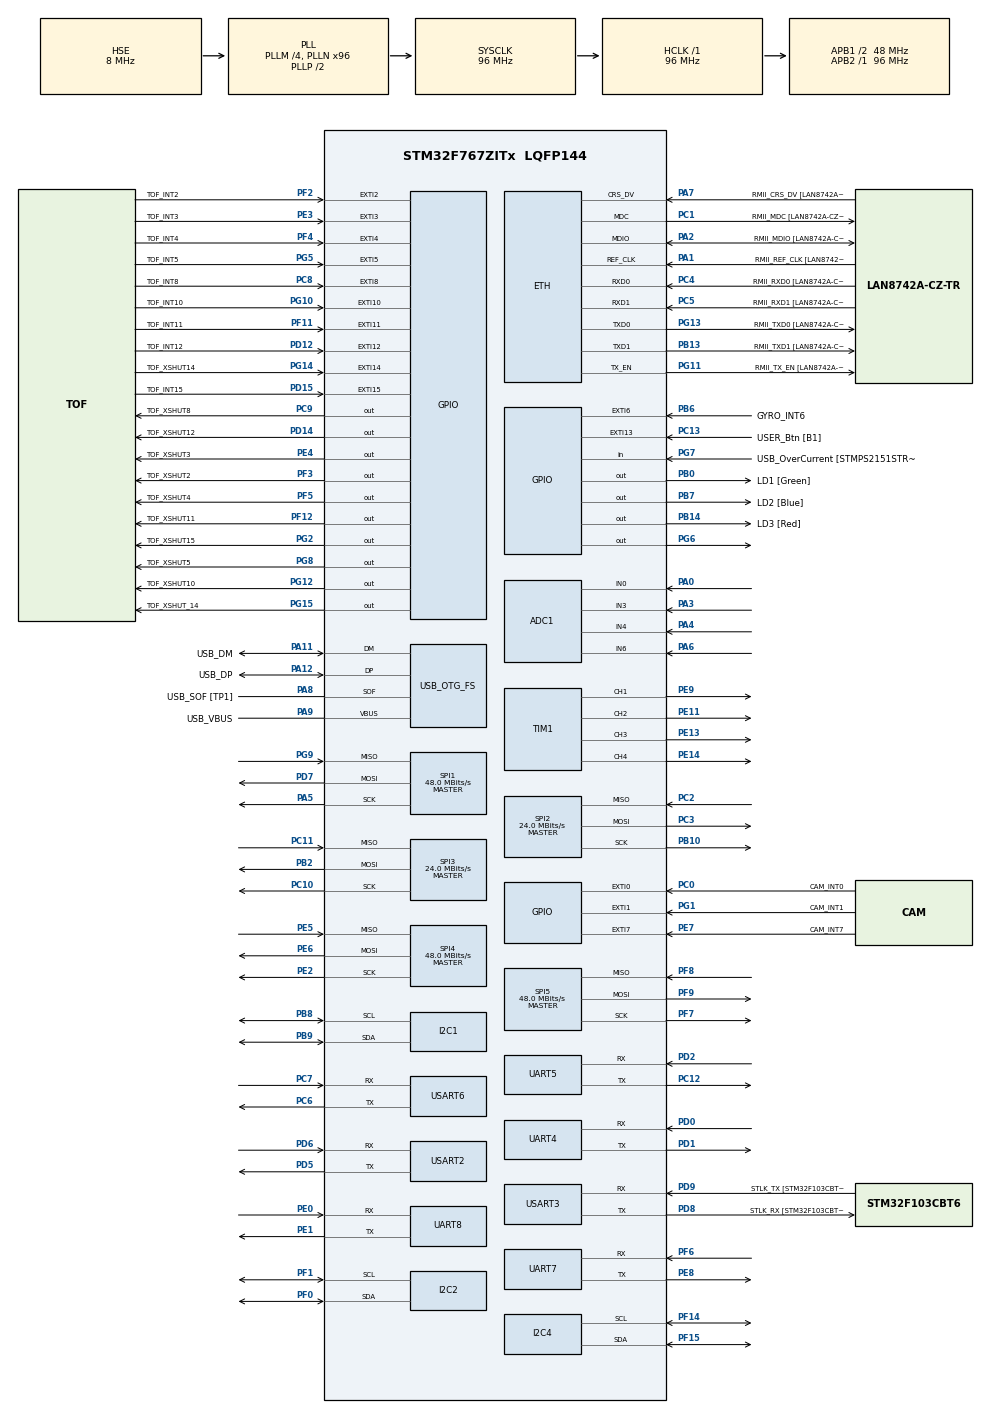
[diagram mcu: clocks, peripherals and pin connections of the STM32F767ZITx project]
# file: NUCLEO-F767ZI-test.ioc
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ADC1.Channel-0\#ChannelRegularConversion=ADC_CHANNEL_0
ADC1.NbrOfConversionFlag=1
ADC1.Rank-0\#ChannelRegularConversion=1
ADC1.SamplingTime-0\#ChannelRegularConversion=ADC_SAMPLETIME_3CYCLES
ADC1.master=1
ETH.MediaInterface=HAL_ETH_RMII_MODE
ETH.PHY_Name=LAN8742A_PHY_ADDRESS
ETH.PHY_Value=0
ETH.PhyAddress=0
I2C1.Timing=0x20303E5D
I2C2.Timing=0x20303E5D
I2C4.Timing=0x20303E5D
Mcu.Family=STM32F7
Mcu.Name=STM32F767ZITx
Mcu.Package=LQFP144
NVIC.PriorityGroup=NVIC_PRIORITYGROUP_4
PA0/WKUP.Signal=ADCx_IN0
PA1.GPIO_Label=RMII_REF_CLK [LAN8742A-CZ-TR_REFCLK0]
PA1.Mode=RMII
PA1.Signal=ETH_REF_CLK
PA10.GPIO_Label=USB_ID
PA10.Signal=USB_OTG_FS_ID
PA11.GPIO_Label=USB_DM
PA11.Mode=Device_Only
PA11.Signal=USB_OTG_FS_DM
PA12.GPIO_Label=USB_DP
PA12.Mode=Device_Only
PA12.Signal=USB_OTG_FS_DP
PA13.GPIO_Label=TMS
PA13.Mode=JTAG_5_pins
PA13.Signal=SYS_JTMS-SWDIO
PA14.GPIO_Label=TCK
PA14.Mode=JTAG_5_pins
PA14.Signal=SYS_JTCK-SWCLK
PA15.Mode=JTAG_5_pins
PA15.Signal=SYS_JTDI
PA2.GPIO_Label=RMII_MDIO [LAN8742A-CZ-TR_MDIO]
PA2.Mode=RMII
PA2.Signal=ETH_MDIO
PA3.Signal=ADCx_IN3
PA4.Signal=ADCx_IN4
PA5.Mode=Full_Duplex_Master
PA5.Signal=SPI1_SCK
PA6.Signal=ADCx_IN6
PA7.GPIO_Label=RMII_CRS_DV [LAN8742A-CZ-TR_CRS_DV]
PA7.Mode=RMII
PA7.Signal=ETH_CRS_DV
PA8.GPIO_Label=USB_SOF [TP1]
PA8.Mode=Activate_SOF_FS
PA8.Signal=USB_OTG_FS_SOF
PA9.GPIO_Label=USB_VBUS
PA9.Mode=Activate_VBUS
PA9.Signal=USB_OTG_FS_VBUS
PB0.GPIO_Label=LD1 [Green]
PB0.Signal=GPIO_Output
PB10.Mode=Full_Duplex_Master
PB10.Signal=SPI2_SCK
PB13.GPIO_Label=RMII_TXD1 [LAN8742A-CZ-TR_TXD1]
PB13.Mode=RMII
PB13.Signal=ETH_TXD1
PB14.GPIO_Label=LD3 [Red]
PB14.Signal=GPIO_Output
PB2.Mode=Full_Duplex_Master
PB2.Signal=SPI3_MOSI
PB3.GPIO_Label=SWO
PB3.Mode=JTAG_5_pins
PB3.Signal=SYS_JTDO-SWO
PB4.Mode=JTAG_5_pins
PB4.Signal=SYS_JTRST
PB6.GPIO_Label=GYRO_INT6
PB6.Signal=GPXTI6
PB7.GPIO_Label=LD2 [Blue]
PB7.Signal=GPIO_Output
PB8.Mode=I2C
PB8.Signal=I2C1_SCL
PB9.Mode=I2C
PB9.Signal=I2C1_SDA
PC0.GPIO_Label=CAM_INT0
PC0.Signal=GPXTI0
PC1.GPIO_Label=RMII_MDC [LAN8742A-CZ-TR_MDC]
PC1.Mode=RMII
PC1.Signal=ETH_MDC
PC10.Mode=Full_Duplex_Master
PC10.Signal=SPI3_SCK
PC11.Mode=Full_Duplex_Master
PC11.Signal=SPI3_MISO
PC12.Mode=Asynchronous
PC12.Signal=UART5_TX
PC13.GPIO_Label=USER_Btn [B1]
PC13.Signal=GPXTI13
PC14/OSC32_IN.Mode=LSE-External-Oscillator
PC14/OSC32_IN.Signal=RCC_OSC32_IN
PC15/OSC32_OUT.Mode=LSE-External-Oscillator
PC15/OSC32_OUT.Signal=RCC_OSC32_OUT
PC2.Mode=Full_Duplex_Master
PC2.Signal=SPI2_MISO
PC3.Mode=Full_Duplex_Master
PC3.Signal=SPI2_MOSI
PC4.GPIO_Label=RMII_RXD0 [LAN8742A-CZ-TR_RXD0]
PC4.Mode=RMII
PC4.Signal=ETH_RXD0
PC5.GPIO_Label=RMII_RXD1 [LAN8742A-CZ-TR_RXD1]
PC5.Mode=RMII
PC5.Signal=ETH_RXD1
PC6.Mode=Asynchronous
PC6.Signal=USART6_TX
PC7.Mode=Asynchronous
PC7.Signal=USART6_RX
PC8.GPIO_Label=TOF_INT8
PC8.Signal=GPXTI8
PC9.GPIO_Label=TOF_XSHUT8
PC9.Signal=GPIO_Output
PD0.Mode=Asynchronous
PD0.Signal=UART4_RX
PD1.Mode=Asynchronous
PD1.Signal=UART4_TX
PD12.GPIO_Label=TOF_INT12
PD12.Signal=GPXTI12
PD14.GPIO_Label=TOF_XSHUT12
PD14.Signal=GPIO_Output
PD15.GPIO_Label=TOF_INT15
PD15.Signal=GPXTI15
PD2.Mode=Asynchronous
PD2.Signal=UART5_RX
PD5.Mode=Asynchronous
PD5.Signal=USART2_TX
PD6.Mode=Asynchronous
PD6.Signal=USART2_RX
PD7.Mode=Full_Duplex_Master
PD7.Signal=SPI1_MOSI
PD8.GPIO_Label=STLK_RX [STM32F103CBT6_PA3]
PD8.Mode=Asynchronous
PD8.Signal=USART3_TX
PD9.GPIO_Label=STLK_TX [STM32F103CBT6_PA2]
PD9.Mode=Asynchronous
PD9.Signal=USART3_RX
PE0.Mode=Asynchronous
PE0.Signal=UART8_RX
PE1.Mode=Asynchronous
PE1.Signal=UART8_TX
PE11.Signal=S_TIM1_CH2
PE13.Signal=S_TIM1_CH3
PE14.Signal=S_TIM1_CH4
PE2.Mode=Full_Duplex_Master
PE2.Signal=SPI4_SCK
PE3.GPIO_Label=TOF_INT3
PE3.Signal=GPXTI3
PE4.GPIO_Label=TOF_XSHUT3
PE4.Signal=GPIO_Output
PE5.Mode=Full_Duplex_Master
PE5.Signal=SPI4_MISO
PE6.Mode=Full_Duplex_Master
PE6.Signal=SPI4_MOSI
PE7.GPIO_Label=CAM_INT7
PE7.Signal=GPXTI7
PE8.Mode=Asynchronous
PE8.Signal=UART7_TX
PE9.Signal=S_TIM1_CH1
PF0.Mode=I2C
PF0.Signal=I2C2_SDA
PF1.Mode=I2C
PF1.Signal=I2C2_SCL
PF11.GPIO_Label=TOF_INT11
PF11.Signal=GPXTI11
PF12.GPIO_Label=TOF_XSHUT11
PF12.Signal=GPIO_Output
PF14.Mode=I2C
PF14.Signal=I2C4_SCL
PF15.Mode=I2C
PF15.Signal=I2C4_SDA
PF2.GPIO_Label=TOF_INT2
PF2.Signal=GPXTI2
PF3.GPIO_Label=TOF_XSHUT2
PF3.Signal=GPIO_Output
PF4.GPIO_Label=TOF_INT4
PF4.Signal=GPXTI4
PF5.GPIO_Label=TOF_XSHUT4
PF5.Signal=GPIO_Output
PF6.Mode=Asynchronous
PF6.Signal=UART7_RX
PF7.Mode=Full_Duplex_Master
PF7.Signal=SPI5_SCK
PF8.Mode=Full_Duplex_Master
PF8.Signal=SPI5_MISO
PF9.Mode=Full_Duplex_Master
PF9.Signal=SPI5_MOSI
PG1.GPIO_Label=CAM_INT1
PG1.Signal=GPXTI1
PG10.GPIO_Label=TOF_INT10
PG10.Signal=GPXTI10
PG11.GPIO_Label=RMII_TX_EN [LAN8742A-CZ-TR_TXEN]
PG11.Mode=RMII
PG11.Signal=ETH_TX_EN
PG12.GPIO_Label=TOF_XSHUT10
PG12.Signal=GPIO_Output
PG13.GPIO_Label=RMII_TXD0 [LAN8742A-CZ-TR_TXD0]
PG13.Mode=RMII
PG13.Signal=ETH_TXD0
PG14.GPIO_Label=TOF_XSHUT14
PG14.Signal=GPXTI14
PG15.GPIO_Label=TOF_XSHUT_14
PG15.Signal=GPIO_Output
PG2.GPIO_Label=TOF_XSHUT15
PG2.Signal=GPIO_Output
PG5.GPIO_Label=TOF_INT5
PG5.Signal=GPXTI5
PG6.Signal=GPIO_Output
PG7.GPIO_Label=USB_OverCurrent [STMPS2151STR_FAULT]
PG7.Signal=GPIO_Input
PG8.GPIO_Label=TOF_XSHUT5
PG8.Signal=GPIO_Output
PG9.Mode=Full_Duplex_Master
PG9.Signal=SPI1_MISO
PH0/OSC_IN.GPIO_Label=MCO [STM32F103CBT6_PA8]
PH0/OSC_IN.Mode=HSE-External-Clock-Source
PH0/OSC_IN.Signal=RCC_OSC_IN
PH1/OSC_OUT.Mode=HSE-External-Clock-Source
PH1/OSC_OUT.Signal=RCC_OSC_OUT
ProjectManager.HeapSize=0x200
ProjectManager.StackSize=0x400
ProjectManager.TargetToolchain=CMake
RCC.48MHZClocksFreq_Value=24000000
RCC.AHBFreq_Value=96000000
RCC.APB1CLKDivider=RCC_HCLK_DIV2
RCC.APB1Freq_Value=48000000
RCC.APB1TimFreq_Value=96000000
RCC.APB2Freq_Value=96000000
RCC.APB2TimFreq_Value=96000000
RCC.CortexFreq_Value=96000000
RCC.HCLKFreq_Value=96000000
RCC.HSE_VALUE=8000000
RCC.HSI_VALUE=16000000
RCC.PLLM=4
RCC.PLLMUL=RCC_PLL_MUL9
RCC.PLLN=96
RCC.PLLQ=4
RCC.PRESCALERUSB=RCC_USBCLKSOURCE_PLL_DIV1_5
RCC.SYSCLKFreq_VALUE=96000000
RCC.SYSCLKSource=RCC_SYSCLKSOURCE_PLLCLK
RCC.SYSCLKSourceVirtual=RCC_SYSCLKSOURCE_PLLCLK
RCC.USBFreq_Value=48000000
RCC.VCOOutputFreq_Value=192000000
SH.ADCx_IN0.0=ADC1_IN0,IN0
SH.ADCx_IN3.0=ADC1_IN3,IN3
SH.ADCx_IN4.0=ADC1_IN4,IN4
SH.ADCx_IN6.0=ADC1_IN6,IN6
SH.S_TIM1_CH1.0=TIM1_CH1,PWM Generation1 CH1
SH.S_TIM1_CH2.0=TIM1_CH2,PWM Generation2 CH2
SH.S_TIM1_CH3.0=TIM1_CH3,PWM Generation3 CH3
SH.S_TIM1_CH4.0=TIM1_CH4,PWM Generation4 CH4
SPI1.CalculateBaudRate=48.0 MBits/s
SPI1.Direction=SPI_DIRECTION_2LINES
SPI1.Mode=SPI_MODE_MASTER
SPI1.VirtualType=VM_MASTER
SPI2.CalculateBaudRate=24.0 MBits/s
SPI2.Direction=SPI_DIRECTION_2LINES
SPI2.Mode=SPI_MODE_MASTER
SPI2.VirtualType=VM_MASTER
SPI3.CalculateBaudRate=24.0 MBits/s
SPI3.Direction=SPI_DIRECTION_2LINES
SPI3.Mode=SPI_MODE_MASTER
SPI3.VirtualType=VM_MASTER
SPI4.CalculateBaudRate=48.0 MBits/s
SPI4.Direction=SPI_DIRECTION_2LINES
SPI4.Mode=SPI_MODE_MASTER
SPI4.VirtualType=VM_MASTER
SPI5.CalculateBaudRate=48.0 MBits/s
SPI5.Direction=SPI_DIRECTION_2LINES
SPI5.Mode=SPI_MODE_MASTER
SPI5.VirtualType=VM_MASTER
TIM1.Channel-PWM\ Generation1\ CH1=TIM_CHANNEL_1
TIM1.Channel-PWM\ Generation2\ CH2=TIM_CHANNEL_2
TIM1.Channel-PWM\ Generation3\ CH3=TIM_CHANNEL_3
TIM1.Channel-PWM\ Generation4\ CH4=TIM_CHANNEL_4
USART2.VirtualMode-Asynchronous=VM_ASYNC
USART3.VirtualMode-Asynchronous=VM_ASYNC
USART6.VirtualMode-Asynchronous=VM_ASYNC
USB_OTG_FS.VirtualMode=Device_Only
VP_TIM1_VS_ClockSourceINT.Mode=Internal
board=NUCLEO-F767ZI

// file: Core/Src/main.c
/* USER CODE BEGIN Header */
/**
  ******************************************************************************
  * @file           : main.c
  * @brief          : Main program body
  ******************************************************************************
  * @attention
  *
  * Copyright (c) 2024 STMicroelectronics.
  * All rights reserved.
  *
  * This software is licensed under terms that can be found in the LICENSE file
  * in the root directory of this software component.
  * If no LICENSE file comes with this software, it is provided AS-IS.
  *
  ******************************************************************************
  */
/* USER CODE END Header */
#include "main.h"
#include "adc.h"
#include "eth.h"
#include "i2c.h"
#include "spi.h"
#include "tim.h"
#include "usart.h"
#include "usb_otg.h"
#include "gpio.h"

/* USER CODE BEGIN Includes */
#include "pid.h"
/* USER CODE END Includes */

void SystemClock_Config(void);

/* USER CODE BEGIN 0 */
void LD2_Blink();
/* USER CODE END 0 */

int main(void)
{

  /* MCU Configuration--------------------------------------------------------*/

  /* Reset of all peripherals, Initializes the Flash interface and the Systick. */
  HAL_Init();

  /* Configure the system clock */
  SystemClock_Config();

  /* Initialize all configured peripherals */
  MX_GPIO_Init();
  MX_ETH_Init();
  MX_I2C1_Init();
  MX_I2C2_Init();
  MX_I2C4_Init();
  MX_SPI1_Init();
  MX_SPI2_Init();
  MX_SPI3_Init();
  MX_UART4_Init();
  MX_UART5_Init();
  MX_UART7_Init();
  MX_UART8_Init();
  MX_USART2_UART_Init();
  MX_USART3_UART_Init();
  MX_USART6_UART_Init();
  MX_USB_OTG_FS_PCD_Init();
  MX_ADC1_Init();
  MX_SPI4_Init();
  MX_SPI5_Init();
  MX_TIM1_Init();

  /* Infinite loop */
  /* USER CODE BEGIN WHILE */
  while (1)
  {
    LD2_Blink();
    /* USER CODE END WHILE */

  }
}

void SystemClock_Config(void)
{
  RCC_OscInitTypeDef RCC_OscInitStruct = {0};
  RCC_ClkInitTypeDef RCC_ClkInitStruct = {0};

  /** Configure LSE Drive Capability
  */
  HAL_PWR_EnableBkUpAccess();

  /** Configure the main internal regulator output voltage
  */
  __HAL_RCC_PWR_CLK_ENABLE();
  __HAL_PWR_VOLTAGESCALING_CONFIG(PWR_REGULATOR_VOLTAGE_SCALE3);

  /** Initializes the RCC Oscillators according to the specified parameters
  * in the RCC_OscInitTypeDef structure.
  */
  RCC_OscInitStruct.OscillatorType = RCC_OSCILLATORTYPE_HSE;
  RCC_OscInitStruct.HSEState = RCC_HSE_BYPASS;
  RCC_OscInitStruct.PLL.PLLState = RCC_PLL_ON;
  RCC_OscInitStruct.PLL.PLLSource = RCC_PLLSOURCE_HSE;
  RCC_OscInitStruct.PLL.PLLM = 4;
  RCC_OscInitStruct.PLL.PLLN = 96;
  RCC_OscInitStruct.PLL.PLLP = RCC_PLLP_DIV2;
  RCC_OscInitStruct.PLL.PLLQ = 4;
  RCC_OscInitStruct.PLL.PLLR = 2;
  if (HAL_RCC_OscConfig(&RCC_OscInitStruct) != HAL_OK)
  {
    Error_Handler();
  }

  /** Activate the Over-Drive mode
  */
  if (HAL_PWREx_EnableOverDrive() != HAL_OK)
  {
    Error_Handler();
  }

  /** Initializes the CPU, AHB and APB buses clocks
  */
  RCC_ClkInitStruct.ClockType = RCC_CLOCKTYPE_HCLK|RCC_CLOCKTYPE_SYSCLK
                              |RCC_CLOCKTYPE_PCLK1|RCC_CLOCKTYPE_PCLK2;
  RCC_ClkInitStruct.SYSCLKSource = RCC_SYSCLKSOURCE_PLLCLK;
  RCC_ClkInitStruct.AHBCLKDivider = RCC_SYSCLK_DIV1;
  RCC_ClkInitStruct.APB1CLKDivider = RCC_HCLK_DIV2;
  RCC_ClkInitStruct.APB2CLKDivider = RCC_HCLK_DIV1;

  if (HAL_RCC_ClockConfig(&RCC_ClkInitStruct, FLASH_LATENCY_3) != HAL_OK)
  {
    Error_Handler();
  }
}

/* USER CODE BEGIN 4 */
void LD2_Blink(){
  HAL_GPIO_TogglePin(LD2_GPIO_Port, LD2_Pin);
  HAL_Delay(100);
}
/* USER CODE END 4 */

void Error_Handler(void)
{
  __disable_irq();
  while (1)
  {
  }
}
